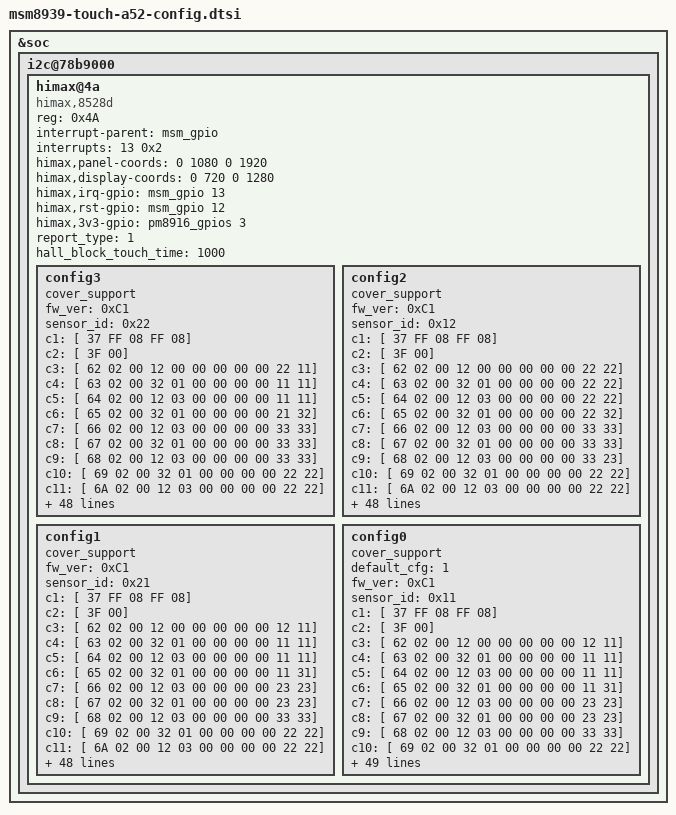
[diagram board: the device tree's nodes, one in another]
&soc {
	i2c@78b9000 { /* BLSP1 QUP5 */
		himax@4a {
			compatible		= "himax,8528d";
			reg			= <0x4A>;
			interrupt-parent	= <&msm_gpio>;
			interrupts		= <13 0x2>;
			himax,panel-coords	= <0 1080 0 1920>;
			himax,display-coords	= <0 720 0 1280>;
			himax,irq-gpio		= <&msm_gpio 13 0x00>;
			himax,rst-gpio		= <&msm_gpio 12 0x00>;
			himax,3v3-gpio		= <&pm8916_gpios 3 0x00>;
			report_type		= <1>;
			hall_block_touch_time	= <1000>;	/* msec */

			config3 {	//TPK GFF
				cover_support;
				fw_ver     	= <0xC1>;
				sensor_id     	= <0x22>;
				c1  = [ 37 FF 08 FF 08];
				c2  = [ 3F 00];
				c3  = [ 62 02 00 12 00 00 00 00 00 22 11];
				c4  = [ 63 02 00 32 01 00 00 00 00 11 11];
				c5  = [ 64 02 00 12 03 00 00 00 00 11 11];
				c6  = [ 65 02 00 32 01 00 00 00 00 21 32];
				c7  = [ 66 02 00 12 03 00 00 00 00 33 33];
				c8  = [ 67 02 00 32 01 00 00 00 00 33 33];
				c9  = [ 68 02 00 12 03 00 00 00 00 33 33];
				c10 = [ 69 02 00 32 01 00 00 00 00 22 22];
				c11 = [ 6A 02 00 12 03 00 00 00 00 22 22];
				c12 = [ 6B 02 00 32 01 00 00 00 00 22 22];
				c13 = [ 6C 02 00 12 03 00 00 00 00 00 00];
				c14 = [ 6D 02 00 02 01 00 00 00 00 00 00];
				c15 = [ 6E 01 00 21 00 00 00 00 00 00 00];
				c16 = [ 6F 01 00 01 02 00 00 00 00 00 00];
				c17 = [ 70 01 00 31 00 00 00 00 00 00 00];
				c18 = [ 7B 03];
				c19 = [ 7C 00 D8 0C];
				c20 = [ 7F 00 04 0A 0A 04 00 00 00];
				c21 = [ A4 94 62 94 86];
				c22 = [ B4 06 01 02 02 02 02 0F 03 07 03
					07 03 07 08];
				c23 = [ B9 01 36];
				c24 = [ BA 00];
				c25 = [ BB 00];
				c26 = [ BC 00 00 00 00];
				c27 = [ BD 04 0C];
				c28 = [ C2 10 00 00 00 00 00 00 00];
				c29 = [ C5 0A 1E 00 10 1A 1E 0B 1E 08 16];
				c30 = [ C6 17 10 19];
				c31 = [ C9 00 00 00 07 01 03 05 09 0B 2D
					28 26 24 22 20 1C 06 02 04 08
					0A 0C 29 27 25 23 21 1D 00 00
					00 00 00 00 00 00 00 00 00 00
					00 00 00 00 00 00 00 00 00 00
					00 00 00 00 00 00 00 00 00 00
					00 00 00 00];
				c32 = [ CB 01 F5 FF FF 01 00 05 00 4F 00
					00 00];
				c33 = [ D0 06 01];
				c34 = [ D3 06 01];
				c35 = [ D5 29 00 00 00 00 00 00 00 00 00
					00 00 00 00 00 00];
				c36 = [ 40 41 5A
					5F 00 F2 10 00 00
					1C 0E 0A 10 09 08 09 0F 0F 0F
					30 2E 40 40 50 00 00 00 00 00
					00 00];
				c37 = [ 40 94 0A F0 83 85 00
					44 22 0F 0F 83 3C 00 00
					11 00 41 42
					1F 58 00 12 00 00
					10 01 3C 64 00 00];
				c38 = [ 40 20 2F 2F 08 1F 00 00 00
					04 06 24 06 06 00 00 00];
				c39 = [ 40 30 2C 05 02 00 D8 0C 00 00 02
					03 00 00 00 00 00
					10 02 80 00 00 00 00 0C];
				c40 = [ 40 00 00 00 00 00 00 00 00
					C8 82 28 00
					0F 19 A0 13
					00 00 04 38 07 80];
				c41 = [ 40 02 60 06 3B 53 33 08 00 7A 02
					23 53 67 0A
					03 5F 08 D8 57 64 00 00 B9 03
					40 56 75 00];
				c42 = [ 40 00 00 00 00 00 00 00 00];
				c43_1=[ 40 11 0B FF FF 12 0A 25 FF 13 09
					24 FF 14 08 23 FF 15 07 22 FF
					10 06 21 FF 0F 05 20 FF 16 04
					1F];
				c43_2=[ 40 FF 17 03 1E FF 18 02 1D FF
					19 01 1C FF 1A 00 FF FF 0E 27
					FF FF 0D 26 FF FF 0C FF 1B FF];
				c44_1=[ 40 33 00 C0 00 19 0A 28 00 00 00
					00 00 00 00 00 00 00 00 00 00
					11 C4 45 C5 48 5C 03 00 00 00
					5C];
				c44_2=[ 40 03 11 03 05 18];
				c45 = [ 40 00 00];
			};

			config2 {	//Truely
				cover_support;
				fw_ver     	= <0xC1>;
				sensor_id     	= <0x12>;
				c1 =  [ 37 FF 08 FF 08];
				c2 =  [ 3F 00];
				c3 =  [ 62 02 00 12 00 00 00 00 00 22 22];
				c4 =  [ 63 02 00 32 01 00 00 00 00 22 22];
				c5 =  [ 64 02 00 12 03 00 00 00 00 22 22];
				c6 =  [ 65 02 00 32 01 00 00 00 00 22 32];
				c7 =  [ 66 02 00 12 03 00 00 00 00 33 33];
				c8 =  [ 67 02 00 32 01 00 00 00 00 33 33];
				c9 =  [ 68 02 00 12 03 00 00 00 00 33 23];
				c10 = [ 69 02 00 32 01 00 00 00 00 22 22];
				c11 = [ 6A 02 00 12 03 00 00 00 00 22 22];
				c12 = [ 6B 02 00 32 01 00 00 00 00 22 22];
				c13 = [ 6C 02 00 12 03 00 00 00 00 00 00];
				c14 = [ 6D 02 00 02 01 00 00 00 00 00 00];
				c15 = [ 6E 01 00 21 00 00 00 00 00 00 00];
				c16 = [ 6F 01 00 01 02 00 00 00 00 00 00];
				c17 = [ 70 01 00 31 00 00 00 00 00 00 00];
				c18 = [ 7B 03];
				c19 = [ 7C 00 D8 0C];
				c20 = [ 7F 00 04 0A 0A 04 00 00 00];
				c21 = [ A4 94 62 94 86];
				c22 = [ B4 06 01 02 02 02 02 0F 03 07 03
					07 03 07 08];
				c23 = [ B9 01 36];
				c24 = [ BA 00];
				c25 = [ BB 00];
				c26 = [ BC 00 00 00 00];
				c27 = [ BD 04 0C];
				c28 = [ C2 10 00 00 00 00 00 00 00];
				c29 = [ C5 0A 1D 00 10 1A 1E 0B 1D 08 16];
				c30 = [ C6 18 10 19];
				c31 = [ C9 00 00 00 07 01 03 05 09 0B 2D
					28 26 24 22 20 1C 06 02 04 08
					0A 0C 29 27 25 23 21 1D 00 00
					00 00 00 00 00 00 00 00 00 00
					00 00 00 00 00 00 00 00 00 00
					00 00 00 00 00 00 00 00 00 00
					00 00 00 00];
				c32 = [ CB 01 F5 FF FF 01 00 05 00 4F 00
					00 00];
				c33 = [ D0 06 01];
				c34 = [ D3 06 01];
				c35 = [ D5 29 00 00 00 00 00 00 00 00 00
					00 00 00 00 00 00];
				c36 = [ 40 21 5A
					5F 00 F2 10 00 00
					1C 0E 0A 10 09 08 09 0F 0F 0F
					30 2E 40 40 50 00 00 00 00 00
					00 00];
				c37 = [ 40 94 0A F0 83 85 00
					44 22 0F 0F 83 3C 00 00
					11 00 41 42
					1F 58 00 12 00 00
					10 01 3C 64 00 00];
				c38 = [ 40 20 2F 2F 08 1F 00 00 00
					04 06 24 06 06 00 00 00];
				c39 = [ 40 30 2C 05 02 00 D8 0C 00 00 02
					03 00 00 00 00 00
					10 02 80 00 00 00 00 0C];
				c40 = [ 40 00 00 00 00 00 00 00 00
					C8 8C 23 00
					0F 19 A0 13
					00 00 04 38 07 80];
				c41 = [ 40 02 60 06 3B 53 33 08 00 7A 02
					23 53 67 0A
					03 5F 08 D8 57 64 00 00 B9 03
					40 56 75 00];
				c42 = [ 40 00 00 00 00 00 00 00 00];
				c43_1=[ 40 11 0B FF FF 12 0A 25 FF 13 09
					24 FF 14 08 23 FF 15 07 22 FF
					10 06 21 FF 0F 05 20 FF 16 04
					1F];
				c43_2=[ 40 FF 17 03 1E FF 18 02 1D FF
					19 01 1C FF 1A 00 FF FF 0E 27
					FF FF 0D 26 FF FF 0C FF 1B FF];
				c44_1=[ 40 33 00 C0 00 19 0A 28 00 00 00
					00 00 00 00 00 00 00 00 00 00
					11 C4 45 C5 48 5C 03 00 00 00
					5C];
				c44_2=[ 40 03 11 03 05 18];
				c45 = [ 40 00 00];
			};

			config1 {	//TPK
				cover_support;
				fw_ver     	= <0xC1>;
				sensor_id     	= <0x21>;
				c1 =  [ 37 FF 08 FF 08];
				c2 =  [ 3F 00];
				c3 =  [ 62 02 00 12 00 00 00 00 00 12 11];
				c4 =  [ 63 02 00 32 01 00 00 00 00 11 11];
				c5 =  [ 64 02 00 12 03 00 00 00 00 11 11];
				c6 =  [ 65 02 00 32 01 00 00 00 00 11 31];
				c7 =  [ 66 02 00 12 03 00 00 00 00 23 23];
				c8 =  [ 67 02 00 32 01 00 00 00 00 23 23];
				c9 =  [ 68 02 00 12 03 00 00 00 00 33 33];
				c10 = [ 69 02 00 32 01 00 00 00 00 22 22];
				c11 = [ 6A 02 00 12 03 00 00 00 00 22 22];
				c12 = [ 6B 02 00 32 01 00 00 00 00 22 22];
				c13 = [ 6C 02 00 12 03 00 00 00 00 00 00];
				c14 = [ 6D 02 00 02 01 00 00 00 00 00 00];
				c15 = [ 6E 01 00 21 00 00 00 00 00 00 00];
				c16 = [ 6F 01 00 01 02 00 00 00 00 00 00];
				c17 = [ 70 01 00 31 00 00 00 00 00 00 00];
				c18 = [ 7B 03];
				c19 = [ 7C 00 D8 0C];
				c20 = [ 7F 00 04 0A 0A 04 00 00 00];
				c21 = [ A4 94 62 94 86];
				c22 = [ B4 06 01 02 02 02 02 0F 03 07 03
					07 03 07 08];
				c23 = [ B9 01 36];
				c24 = [ BA 00];
				c25 = [ BB 00];
				c26 = [ BC 00 00 00 00];
				c27 = [ BD 04 0C];
				c28 = [ C2 10 00 00 00 00 00 00 00];
				c29 = [ C5 0A 1F 00 10 1B 1E 0B 1F 08 16];
				c30 = [ C6 17 10 19];
				c31 = [ C9 00 00 00 07 01 03 05 09 0B 2D
					28 26 24 22 20 1C 06 02 04 08
					0A 0C 29 27 25 23 21 1D 00 00
					00 00 00 00 00 00 00 00 00 00
					00 00 00 00 00 00 00 00 00 00
					00 00 00 00 00 00 00 00 00 00
					00 00 00 00];
				c32 = [ CB 01 F5 FF FF 01 00 05 00 4F 00
					00 00];
				c33 = [ D0 06 01];
				c34 = [ D3 06 01];
				c35 = [ D5 29 00 00 00 00 00 00 00 00 00
					00 00 00 00 00 00];
				c36 = [ 40 07 5A
					5F 00 F2 10 00 00
					1C 0E 0A 10 09 08 09 0F 0F 0F
					30 2E 40 40 50 00 00 00 00 00
					00 00];
				c37 = [ 40 94 0A F0 83 85 00
					44 22 0F 0F 83 3C 00 00
					11 00 41 42
					1F 58 00 12 00 00
					10 01 3C 64 00 00];
				c38 = [ 40 20 2F 2F 08 1F 00 00 00
					04 06 24 06 06 00 00 00];
				c39 = [ 40 30 2C 05 02 00 D8 0C 00 00 02
					03 00 00 00 00 00
					10 02 80 00 00 00 00 0C];
				c40 = [ 40 00 00 00 00 00 00 00 00
					C8 78 1E 00
					0F 19 A0 13
					00 00 04 38 07 80];
				c41 = [ 40 02 60 06 3B 53 33 08 00 7A 02
					23 53 67 0A
					03 5F 08 D8 57 64 00 00 B9 03
					40 56 75 00];
				c42 = [ 40 00 00 00 00 00 00 00 00];
				c43_1=[ 40 11 0B FF FF 12 0A 25 FF 13 09
					24 FF 14 08 23 FF 15 07 22 FF
					10 06 21 FF 0F 05 20 FF 16 04
					1F];
				c43_2=[ 40 FF 17 03 1E FF 18 02 1D FF
					19 01 1C FF 1A 00 FF FF 0E 27
					FF FF 0D 26 FF FF 0C FF 1B FF];
				c44_1=[ 40 33 00 C0 00 19 0A 28 00 00 00
					00 00 00 00 00 00 00 00 00 00
					11 C4 45 C5 48 5C 03 00 00 00
					5C];
				c44_2=[ 40 03 11 03 05 18];
				c45 = [ 40 00 00];
			};

			config0 {	//Disconnected
				cover_support;
				default_cfg   	= <1>;
				fw_ver     	= <0xC1>;
				sensor_id     	= <0x11>;
				c1 =  [ 37 FF 08 FF 08];
				c2 =  [ 3F 00];
				c3 =  [ 62 02 00 12 00 00 00 00 00 12 11];
				c4 =  [ 63 02 00 32 01 00 00 00 00 11 11];
				c5 =  [ 64 02 00 12 03 00 00 00 00 11 11];
				c6 =  [ 65 02 00 32 01 00 00 00 00 11 31];
				c7 =  [ 66 02 00 12 03 00 00 00 00 23 23];
				c8 =  [ 67 02 00 32 01 00 00 00 00 23 23];
				c9 =  [ 68 02 00 12 03 00 00 00 00 33 33];
				c10 = [ 69 02 00 32 01 00 00 00 00 22 22];
				c11 = [ 6A 02 00 12 03 00 00 00 00 22 22];
				c12 = [ 6B 02 00 32 01 00 00 00 00 22 22];
				c13 = [ 6C 02 00 12 03 00 00 00 00 00 00];
				c14 = [ 6D 02 00 02 01 00 00 00 00 00 00];
				c15 = [ 6E 01 00 21 00 00 00 00 00 00 00];
				c16 = [ 6F 01 00 01 02 00 00 00 00 00 00];
				c17 = [ 70 01 00 31 00 00 00 00 00 00 00];
				c18 = [ 7B 03];
				c19 = [ 7C 00 D8 0C];
				c20 = [ 7F 00 04 0A 0A 04 00 00 00];
				c21 = [ A4 94 62 94 86];
				c22 = [ B4 06 01 02 02 02 02 0F 03 07 03
					07 03 07 08];
				c23 = [ B9 01 36];
				c24 = [ BA 00];
				c25 = [ BB 00];
				c26 = [ BC 00 00 00 00];
				c27 = [ BD 04 0C];
				c28 = [ C2 10 00 00 00 00 00 00 00];
				c29 = [ C5 0A 1F 00 10 1B 1E 0B 1F 08 16];
				c30 = [ C6 17 10 19];
				c31 = [ C9 00 00 00 07 01 03 05 09 0B 2D
					28 26 24 22 20 1C 06 02 04 08
					0A 0C 29 27 25 23 21 1D 00 00
					00 00 00 00 00 00 00 00 00 00
					00 00 00 00 00 00 00 00 00 00
					00 00 00 00 00 00 00 00 00 00
					00 00 00 00];
				c32 = [ CB 01 F5 FF FF 01 00 05 00 4F 00
					00 00];
				c33 = [ D0 06 01];
				c34 = [ D3 06 01];
				c35 = [ D5 29 00 00 00 00 00 00 00 00 00
					00 00 00 00 00 00];
				c36 = [ 40 07 5A
					5F 00 F2 10 00 00
					1C 0E 0A 10 09 08 09 0F 0F 0F
					30 2E 40 40 50 00 00 00 00 00
					00 00];
				c37 = [ 40 94 0A F0 83 85 00
					44 22 0F 0F 83 3C 00 00
					11 00 41 42
					1F 58 00 12 00 00
					10 01 3C 64 00 00];
				c38 = [ 40 20 2F 2F 08 1F 00 00 00
					04 06 24 06 06 00 00 00];
				c39 = [ 40 30 2C 05 02 00 D8 0C 00 00 02
					03 00 00 00 00 00
					10 02 80 00 00 00 00 0C];
				c40 = [ 40 00 00 00 00 00 00 00 00
					C8 78 1E 00
					0F 19 A0 13
					00 00 04 38 07 80];
				c41 = [ 40 02 60 06 3B 53 33 08 00 7A 02
					23 53 67 0A
					03 5F 08 D8 57 64 00 00 B9 03
					40 56 75 00];
				c42 = [ 40 00 00 00 00 00 00 00 00];
				c43_1=[ 40 11 0B FF FF 12 0A 25 FF 13 09
					24 FF 14 08 23 FF 15 07 22 FF
					10 06 21 FF 0F 05 20 FF 16 04
					1F];
				c43_2=[ 40 FF 17 03 1E FF 18 02 1D FF
					19 01 1C FF 1A 00 FF FF 0E 27
					FF FF 0D 26 FF FF 0C FF 1B FF];
				c44_1=[ 40 33 00 C0 00 19 0A 28 00 00 00
					00 00 00 00 00 00 00 00 00 00
					11 C4 45 C5 48 5C 03 00 00 00
					5C];
				c44_2=[ 40 03 11 03 05 18];
				c45 = [ 40 00 00];
			};
		};
	};
};
